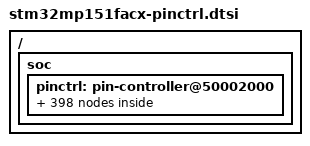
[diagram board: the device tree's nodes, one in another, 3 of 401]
/*
 * NOTE: Autogenerated file using genpinctrl.py
 *
 * SPDX-License-Identifier: Apache-2.0
 */

#include <dt-bindings/pinctrl/stm32-pinctrl.h>

/ {
	soc {
		pinctrl: pin-controller@50002000 {

			/* ADC_IN / ADC_INN / ADC_INP */

			adc1_inp16_pa0: adc1_inp16_pa0 {
				pinmux = <STM32_PINMUX('A', 0, ANALOG)>;
			};

			adc1_inn16_pa1: adc1_inn16_pa1 {
				pinmux = <STM32_PINMUX('A', 1, ANALOG)>;
			};

			adc1_inp17_pa1: adc1_inp17_pa1 {
				pinmux = <STM32_PINMUX('A', 1, ANALOG)>;
			};

			adc1_inp14_pa2: adc1_inp14_pa2 {
				pinmux = <STM32_PINMUX('A', 2, ANALOG)>;
			};

			adc1_inp15_pa3: adc1_inp15_pa3 {
				pinmux = <STM32_PINMUX('A', 3, ANALOG)>;
			};

			adc1_inp18_pa4: adc1_inp18_pa4 {
				pinmux = <STM32_PINMUX('A', 4, ANALOG)>;
			};

			adc1_inn18_pa5: adc1_inn18_pa5 {
				pinmux = <STM32_PINMUX('A', 5, ANALOG)>;
			};

			adc1_inp19_pa5: adc1_inp19_pa5 {
				pinmux = <STM32_PINMUX('A', 5, ANALOG)>;
			};

			adc1_inp3_pa6: adc1_inp3_pa6 {
				pinmux = <STM32_PINMUX('A', 6, ANALOG)>;
			};

			adc1_inn3_pa7: adc1_inn3_pa7 {
				pinmux = <STM32_PINMUX('A', 7, ANALOG)>;
			};

			adc1_inp7_pa7: adc1_inp7_pa7 {
				pinmux = <STM32_PINMUX('A', 7, ANALOG)>;
			};

			adc1_inn5_pb0: adc1_inn5_pb0 {
				pinmux = <STM32_PINMUX('B', 0, ANALOG)>;
			};

			adc1_inp9_pb0: adc1_inp9_pb0 {
				pinmux = <STM32_PINMUX('B', 0, ANALOG)>;
			};

			adc1_inp5_pb1: adc1_inp5_pb1 {
				pinmux = <STM32_PINMUX('B', 1, ANALOG)>;
			};

			adc1_inp10_pc0: adc1_inp10_pc0 {
				pinmux = <STM32_PINMUX('C', 0, ANALOG)>;
			};

			adc1_inn10_pc1: adc1_inn10_pc1 {
				pinmux = <STM32_PINMUX('C', 1, ANALOG)>;
			};

			adc1_inp11_pc1: adc1_inp11_pc1 {
				pinmux = <STM32_PINMUX('C', 1, ANALOG)>;
			};

			adc1_inn11_pc2: adc1_inn11_pc2 {
				pinmux = <STM32_PINMUX('C', 2, ANALOG)>;
			};

			adc1_inp12_pc2: adc1_inp12_pc2 {
				pinmux = <STM32_PINMUX('C', 2, ANALOG)>;
			};

			adc1_inn12_pc3: adc1_inn12_pc3 {
				pinmux = <STM32_PINMUX('C', 3, ANALOG)>;
			};

			adc1_inp13_pc3: adc1_inp13_pc3 {
				pinmux = <STM32_PINMUX('C', 3, ANALOG)>;
			};

			adc1_inp4_pc4: adc1_inp4_pc4 {
				pinmux = <STM32_PINMUX('C', 4, ANALOG)>;
			};

			adc1_inn4_pc5: adc1_inn4_pc5 {
				pinmux = <STM32_PINMUX('C', 5, ANALOG)>;
			};

			adc1_inp8_pc5: adc1_inp8_pc5 {
				pinmux = <STM32_PINMUX('C', 5, ANALOG)>;
			};

			adc1_inp2_pf11: adc1_inp2_pf11 {
				pinmux = <STM32_PINMUX('F', 11, ANALOG)>;
			};

			adc1_inn2_pf12: adc1_inn2_pf12 {
				pinmux = <STM32_PINMUX('F', 12, ANALOG)>;
			};

			adc1_inp6_pf12: adc1_inp6_pf12 {
				pinmux = <STM32_PINMUX('F', 12, ANALOG)>;
			};

			adc2_inp18_pa4: adc2_inp18_pa4 {
				pinmux = <STM32_PINMUX('A', 4, ANALOG)>;
			};

			adc2_inn18_pa5: adc2_inn18_pa5 {
				pinmux = <STM32_PINMUX('A', 5, ANALOG)>;
			};

			adc2_inp19_pa5: adc2_inp19_pa5 {
				pinmux = <STM32_PINMUX('A', 5, ANALOG)>;
			};

			adc2_inp3_pa6: adc2_inp3_pa6 {
				pinmux = <STM32_PINMUX('A', 6, ANALOG)>;
			};

			adc2_inn3_pa7: adc2_inn3_pa7 {
				pinmux = <STM32_PINMUX('A', 7, ANALOG)>;
			};

			adc2_inp7_pa7: adc2_inp7_pa7 {
				pinmux = <STM32_PINMUX('A', 7, ANALOG)>;
			};

			adc2_inn5_pb0: adc2_inn5_pb0 {
				pinmux = <STM32_PINMUX('B', 0, ANALOG)>;
			};

			adc2_inp9_pb0: adc2_inp9_pb0 {
				pinmux = <STM32_PINMUX('B', 0, ANALOG)>;
			};

			adc2_inp5_pb1: adc2_inp5_pb1 {
				pinmux = <STM32_PINMUX('B', 1, ANALOG)>;
			};

			adc2_inp10_pc0: adc2_inp10_pc0 {
				pinmux = <STM32_PINMUX('C', 0, ANALOG)>;
			};

			adc2_inn10_pc1: adc2_inn10_pc1 {
				pinmux = <STM32_PINMUX('C', 1, ANALOG)>;
			};

			adc2_inp11_pc1: adc2_inp11_pc1 {
				pinmux = <STM32_PINMUX('C', 1, ANALOG)>;
			};

			adc2_inp4_pc4: adc2_inp4_pc4 {
				pinmux = <STM32_PINMUX('C', 4, ANALOG)>;
			};

			adc2_inn4_pc5: adc2_inn4_pc5 {
				pinmux = <STM32_PINMUX('C', 5, ANALOG)>;
			};

			adc2_inp8_pc5: adc2_inp8_pc5 {
				pinmux = <STM32_PINMUX('C', 5, ANALOG)>;
			};

			adc2_inp2_pf13: adc2_inp2_pf13 {
				pinmux = <STM32_PINMUX('F', 13, ANALOG)>;
			};

			adc2_inn2_pf14: adc2_inn2_pf14 {
				pinmux = <STM32_PINMUX('F', 14, ANALOG)>;
			};

			adc2_inp6_pf14: adc2_inp6_pf14 {
				pinmux = <STM32_PINMUX('F', 14, ANALOG)>;
			};

			/* DAC_OUT */

			dac1_out1_pa4: dac1_out1_pa4 {
				pinmux = <STM32_PINMUX('A', 4, ANALOG)>;
			};

			dac1_out2_pa5: dac1_out2_pa5 {
				pinmux = <STM32_PINMUX('A', 5, ANALOG)>;
			};

			/* I2C_SCL */

			i2c1_scl_pb6: i2c1_scl_pb6 {
				pinmux = <STM32_PINMUX('B', 6, AF4)>;
				bias-pull-up;
				drive-open-drain;
			};

			i2c1_scl_pb8: i2c1_scl_pb8 {
				pinmux = <STM32_PINMUX('B', 8, AF4)>;
				bias-pull-up;
				drive-open-drain;
			};

			i2c1_scl_pd12: i2c1_scl_pd12 {
				pinmux = <STM32_PINMUX('D', 12, AF5)>;
				bias-pull-up;
				drive-open-drain;
			};

			i2c1_scl_pf14: i2c1_scl_pf14 {
				pinmux = <STM32_PINMUX('F', 14, AF5)>;
				bias-pull-up;
				drive-open-drain;
			};

			i2c1_scl_ph11: i2c1_scl_ph11 {
				pinmux = <STM32_PINMUX('H', 11, AF5)>;
				bias-pull-up;
				drive-open-drain;
			};

			i2c2_scl_pb10: i2c2_scl_pb10 {
				pinmux = <STM32_PINMUX('B', 10, AF4)>;
				bias-pull-up;
				drive-open-drain;
			};

			i2c2_scl_pd7: i2c2_scl_pd7 {
				pinmux = <STM32_PINMUX('D', 7, AF4)>;
				bias-pull-up;
				drive-open-drain;
			};

			i2c2_scl_pf1: i2c2_scl_pf1 {
				pinmux = <STM32_PINMUX('F', 1, AF4)>;
				bias-pull-up;
				drive-open-drain;
			};

			i2c2_scl_ph4: i2c2_scl_ph4 {
				pinmux = <STM32_PINMUX('H', 4, AF4)>;
				bias-pull-up;
				drive-open-drain;
			};

			i2c2_scl_pz0: i2c2_scl_pz0 {
				pinmux = <STM32_PINMUX('Z', 0, AF3)>;
				bias-pull-up;
				drive-open-drain;
			};

			i2c2_scl_pz2: i2c2_scl_pz2 {
				pinmux = <STM32_PINMUX('Z', 2, AF3)>;
				bias-pull-up;
				drive-open-drain;
			};

			i2c2_scl_pz4: i2c2_scl_pz4 {
				pinmux = <STM32_PINMUX('Z', 4, AF3)>;
				bias-pull-up;
				drive-open-drain;
			};

			i2c2_scl_pz6: i2c2_scl_pz6 {
				pinmux = <STM32_PINMUX('Z', 6, AF3)>;
				bias-pull-up;
				drive-open-drain;
			};

			i2c3_scl_pa8: i2c3_scl_pa8 {
				pinmux = <STM32_PINMUX('A', 8, AF4)>;
				bias-pull-up;
				drive-open-drain;
			};

			i2c3_scl_ph7: i2c3_scl_ph7 {
				pinmux = <STM32_PINMUX('H', 7, AF4)>;
				bias-pull-up;
				drive-open-drain;
			};

			i2c4_scl_pb6: i2c4_scl_pb6 {
				pinmux = <STM32_PINMUX('B', 6, AF6)>;
				bias-pull-up;
				drive-open-drain;
			};

			i2c4_scl_pb8: i2c4_scl_pb8 {
				pinmux = <STM32_PINMUX('B', 8, AF6)>;
				bias-pull-up;
				drive-open-drain;
			};

			i2c4_scl_pd12: i2c4_scl_pd12 {
				pinmux = <STM32_PINMUX('D', 12, AF4)>;
				bias-pull-up;
				drive-open-drain;
			};

			i2c4_scl_pe2: i2c4_scl_pe2 {
				pinmux = <STM32_PINMUX('E', 2, AF4)>;
				bias-pull-up;
				drive-open-drain;
			};

			i2c4_scl_pf14: i2c4_scl_pf14 {
				pinmux = <STM32_PINMUX('F', 14, AF4)>;
				bias-pull-up;
				drive-open-drain;
			};

			i2c4_scl_ph11: i2c4_scl_ph11 {
				pinmux = <STM32_PINMUX('H', 11, AF4)>;
				bias-pull-up;
				drive-open-drain;
			};

			i2c4_scl_pz4: i2c4_scl_pz4 {
				pinmux = <STM32_PINMUX('Z', 4, AF6)>;
				bias-pull-up;
				drive-open-drain;
			};

			i2c5_scl_pa11: i2c5_scl_pa11 {
				pinmux = <STM32_PINMUX('A', 11, AF4)>;
				bias-pull-up;
				drive-open-drain;
			};

			i2c5_scl_pd1: i2c5_scl_pd1 {
				pinmux = <STM32_PINMUX('D', 1, AF4)>;
				bias-pull-up;
				drive-open-drain;
			};

			i2c5_scl_pz4: i2c5_scl_pz4 {
				pinmux = <STM32_PINMUX('Z', 4, AF4)>;
				bias-pull-up;
				drive-open-drain;
			};

			i2c6_scl_pa11: i2c6_scl_pa11 {
				pinmux = <STM32_PINMUX('A', 11, AF2)>;
				bias-pull-up;
				drive-open-drain;
			};

			i2c6_scl_pd1: i2c6_scl_pd1 {
				pinmux = <STM32_PINMUX('D', 1, AF2)>;
				bias-pull-up;
				drive-open-drain;
			};

			i2c6_scl_pz0: i2c6_scl_pz0 {
				pinmux = <STM32_PINMUX('Z', 0, AF2)>;
				bias-pull-up;
				drive-open-drain;
			};

			i2c6_scl_pz2: i2c6_scl_pz2 {
				pinmux = <STM32_PINMUX('Z', 2, AF2)>;
				bias-pull-up;
				drive-open-drain;
			};

			i2c6_scl_pz4: i2c6_scl_pz4 {
				pinmux = <STM32_PINMUX('Z', 4, AF2)>;
				bias-pull-up;
				drive-open-drain;
			};

			i2c6_scl_pz6: i2c6_scl_pz6 {
				pinmux = <STM32_PINMUX('Z', 6, AF2)>;
				bias-pull-up;
				drive-open-drain;
			};

			/* I2C_SDA */

			i2c1_sda_pb7: i2c1_sda_pb7 {
				pinmux = <STM32_PINMUX('B', 7, AF4)>;
				bias-pull-up;
				drive-open-drain;
			};

			i2c1_sda_pb9: i2c1_sda_pb9 {
				pinmux = <STM32_PINMUX('B', 9, AF4)>;
				bias-pull-up;
				drive-open-drain;
			};

			i2c1_sda_pd13: i2c1_sda_pd13 {
				pinmux = <STM32_PINMUX('D', 13, AF5)>;
				bias-pull-up;
				drive-open-drain;
			};

			i2c1_sda_pf15: i2c1_sda_pf15 {
				pinmux = <STM32_PINMUX('F', 15, AF5)>;
				bias-pull-up;
				drive-open-drain;
			};

			i2c1_sda_ph12: i2c1_sda_ph12 {
				pinmux = <STM32_PINMUX('H', 12, AF5)>;
				bias-pull-up;
				drive-open-drain;
			};

			i2c2_sda_pb11: i2c2_sda_pb11 {
				pinmux = <STM32_PINMUX('B', 11, AF4)>;
				bias-pull-up;
				drive-open-drain;
			};

			i2c2_sda_pf0: i2c2_sda_pf0 {
				pinmux = <STM32_PINMUX('F', 0, AF4)>;
				bias-pull-up;
				drive-open-drain;
			};

			i2c2_sda_pg15: i2c2_sda_pg15 {
				pinmux = <STM32_PINMUX('G', 15, AF4)>;
				bias-pull-up;
				drive-open-drain;
			};

			i2c2_sda_ph5: i2c2_sda_ph5 {
				pinmux = <STM32_PINMUX('H', 5, AF4)>;
				bias-pull-up;
				drive-open-drain;
			};

			i2c2_sda_pz1: i2c2_sda_pz1 {
				pinmux = <STM32_PINMUX('Z', 1, AF3)>;
				bias-pull-up;
				drive-open-drain;
			};

			i2c2_sda_pz3: i2c2_sda_pz3 {
				pinmux = <STM32_PINMUX('Z', 3, AF3)>;
				bias-pull-up;
				drive-open-drain;
			};

			i2c2_sda_pz5: i2c2_sda_pz5 {
				pinmux = <STM32_PINMUX('Z', 5, AF3)>;
				bias-pull-up;
				drive-open-drain;
			};

			i2c2_sda_pz7: i2c2_sda_pz7 {
				pinmux = <STM32_PINMUX('Z', 7, AF3)>;
				bias-pull-up;
				drive-open-drain;
			};

			i2c3_sda_pc9: i2c3_sda_pc9 {
				pinmux = <STM32_PINMUX('C', 9, AF4)>;
				bias-pull-up;
				drive-open-drain;
			};

			i2c3_sda_ph8: i2c3_sda_ph8 {
				pinmux = <STM32_PINMUX('H', 8, AF4)>;
				bias-pull-up;
				drive-open-drain;
			};

			i2c4_sda_pb7: i2c4_sda_pb7 {
				pinmux = <STM32_PINMUX('B', 7, AF6)>;
				bias-pull-up;
				drive-open-drain;
			};

			i2c4_sda_pb9: i2c4_sda_pb9 {
				pinmux = <STM32_PINMUX('B', 9, AF6)>;
				bias-pull-up;
				drive-open-drain;
			};

			i2c4_sda_pd13: i2c4_sda_pd13 {
				pinmux = <STM32_PINMUX('D', 13, AF4)>;
				bias-pull-up;
				drive-open-drain;
			};

			i2c4_sda_pf15: i2c4_sda_pf15 {
				pinmux = <STM32_PINMUX('F', 15, AF4)>;
				bias-pull-up;
				drive-open-drain;
			};

			i2c4_sda_ph12: i2c4_sda_ph12 {
				pinmux = <STM32_PINMUX('H', 12, AF4)>;
				bias-pull-up;
				drive-open-drain;
			};

			i2c4_sda_pz1: i2c4_sda_pz1 {
				pinmux = <STM32_PINMUX('Z', 1, AF6)>;
				bias-pull-up;
				drive-open-drain;
			};

			i2c4_sda_pz3: i2c4_sda_pz3 {
				pinmux = <STM32_PINMUX('Z', 3, AF6)>;
				bias-pull-up;
				drive-open-drain;
			};

			i2c4_sda_pz5: i2c4_sda_pz5 {
				pinmux = <STM32_PINMUX('Z', 5, AF6)>;
				bias-pull-up;
				drive-open-drain;
			};

			i2c5_sda_pa12: i2c5_sda_pa12 {
				pinmux = <STM32_PINMUX('A', 12, AF4)>;
				bias-pull-up;
				drive-open-drain;
			};

			i2c5_sda_pd0: i2c5_sda_pd0 {
				pinmux = <STM32_PINMUX('D', 0, AF4)>;
				bias-pull-up;
				drive-open-drain;
			};

			i2c5_sda_pz1: i2c5_sda_pz1 {
				pinmux = <STM32_PINMUX('Z', 1, AF4)>;
				bias-pull-up;
				drive-open-drain;
			};

			i2c5_sda_pz3: i2c5_sda_pz3 {
				pinmux = <STM32_PINMUX('Z', 3, AF4)>;
				bias-pull-up;
				drive-open-drain;
			};

			i2c5_sda_pz5: i2c5_sda_pz5 {
				pinmux = <STM32_PINMUX('Z', 5, AF4)>;
				bias-pull-up;
				drive-open-drain;
			};

			i2c6_sda_pa12: i2c6_sda_pa12 {
				pinmux = <STM32_PINMUX('A', 12, AF2)>;
				bias-pull-up;
				drive-open-drain;
			};

			i2c6_sda_pd0: i2c6_sda_pd0 {
				pinmux = <STM32_PINMUX('D', 0, AF2)>;
				bias-pull-up;
				drive-open-drain;
			};

			i2c6_sda_pz1: i2c6_sda_pz1 {
				pinmux = <STM32_PINMUX('Z', 1, AF2)>;
				bias-pull-up;
				drive-open-drain;
			};

			i2c6_sda_pz3: i2c6_sda_pz3 {
				pinmux = <STM32_PINMUX('Z', 3, AF2)>;
				bias-pull-up;
				drive-open-drain;
			};

			i2c6_sda_pz5: i2c6_sda_pz5 {
				pinmux = <STM32_PINMUX('Z', 5, AF2)>;
				bias-pull-up;
				drive-open-drain;
			};

			i2c6_sda_pz7: i2c6_sda_pz7 {
				pinmux = <STM32_PINMUX('Z', 7, AF2)>;
				bias-pull-up;
				drive-open-drain;
			};

			/* I2S_CK */

			i2s1_ck_pa5: i2s1_ck_pa5 {
				pinmux = <STM32_PINMUX('A', 5, AF5)>;
			};

			i2s1_ck_pb3: i2s1_ck_pb3 {
				pinmux = <STM32_PINMUX('B', 3, AF5)>;
			};

			i2s1_ck_pz0: i2s1_ck_pz0 {
				pinmux = <STM32_PINMUX('Z', 0, AF5)>;
			};

			i2s2_ck_pa9: i2s2_ck_pa9 {
				pinmux = <STM32_PINMUX('A', 9, AF5)>;
			};

			i2s2_ck_pb10: i2s2_ck_pb10 {
				pinmux = <STM32_PINMUX('B', 10, AF5)>;
			};

			i2s2_ck_pb13: i2s2_ck_pb13 {
				pinmux = <STM32_PINMUX('B', 13, AF5)>;
			};

			i2s2_ck_pd3: i2s2_ck_pd3 {
				pinmux = <STM32_PINMUX('D', 3, AF5)>;
			};

			i2s2_ck_pi1: i2s2_ck_pi1 {
				pinmux = <STM32_PINMUX('I', 1, AF5)>;
			};

			i2s3_ck_pb3: i2s3_ck_pb3 {
				pinmux = <STM32_PINMUX('B', 3, AF6)>;
			};

			i2s3_ck_pc10: i2s3_ck_pc10 {
				pinmux = <STM32_PINMUX('C', 10, AF6)>;
			};

			i2s3_ck_pe0: i2s3_ck_pe0 {
				pinmux = <STM32_PINMUX('E', 0, AF5)>;
			};

			/* I2S_WS */

			i2s1_ws_pa4: i2s1_ws_pa4 {
				pinmux = <STM32_PINMUX('A', 4, AF5)>;
			};

			i2s1_ws_pa15: i2s1_ws_pa15 {
				pinmux = <STM32_PINMUX('A', 15, AF5)>;
			};

			i2s1_ws_pz3: i2s1_ws_pz3 {
				pinmux = <STM32_PINMUX('Z', 3, AF5)>;
			};

			i2s2_ws_pa11: i2s2_ws_pa11 {
				pinmux = <STM32_PINMUX('A', 11, AF5)>;
			};

			i2s2_ws_pb4: i2s2_ws_pb4 {
				pinmux = <STM32_PINMUX('B', 4, AF7)>;
			};

			i2s2_ws_pb9: i2s2_ws_pb9 {
				pinmux = <STM32_PINMUX('B', 9, AF5)>;
			};

			i2s2_ws_pb12: i2s2_ws_pb12 {
				pinmux = <STM32_PINMUX('B', 12, AF5)>;
			};

			i2s2_ws_pi0: i2s2_ws_pi0 {
				pinmux = <STM32_PINMUX('I', 0, AF5)>;
			};

			i2s3_ws_pa4: i2s3_ws_pa4 {
				pinmux = <STM32_PINMUX('A', 4, AF6)>;
			};

			i2s3_ws_pa10: i2s3_ws_pa10 {
				pinmux = <STM32_PINMUX('A', 10, AF5)>;
			};

			i2s3_ws_pa15: i2s3_ws_pa15 {
				pinmux = <STM32_PINMUX('A', 15, AF6)>;
			};

			/* SPI_MISO */

			spi1_miso_pa6: spi1_miso_pa6 {
				pinmux = <STM32_PINMUX('A', 6, AF5)>;
				bias-pull-down;
			};

			spi1_miso_pb4: spi1_miso_pb4 {
				pinmux = <STM32_PINMUX('B', 4, AF5)>;
				bias-pull-down;
			};

			spi1_miso_pz1: spi1_miso_pz1 {
				pinmux = <STM32_PINMUX('Z', 1, AF5)>;
				bias-pull-down;
			};

			spi2_miso_pb14: spi2_miso_pb14 {
				pinmux = <STM32_PINMUX('B', 14, AF5)>;
				bias-pull-down;
			};

			spi2_miso_pc2: spi2_miso_pc2 {
				pinmux = <STM32_PINMUX('C', 2, AF5)>;
				bias-pull-down;
			};

			spi2_miso_pi2: spi2_miso_pi2 {
				pinmux = <STM32_PINMUX('I', 2, AF5)>;
				bias-pull-down;
			};

			spi3_miso_pb4: spi3_miso_pb4 {
				pinmux = <STM32_PINMUX('B', 4, AF6)>;
				bias-pull-down;
			};

			spi3_miso_pc11: spi3_miso_pc11 {
				pinmux = <STM32_PINMUX('C', 11, AF6)>;
				bias-pull-down;
			};

			spi3_miso_pd10: spi3_miso_pd10 {
				pinmux = <STM32_PINMUX('D', 10, AF5)>;
				bias-pull-down;
			};

			spi4_miso_pe5: spi4_miso_pe5 {
				pinmux = <STM32_PINMUX('E', 5, AF5)>;
				bias-pull-down;
			};

			spi4_miso_pe13: spi4_miso_pe13 {
				pinmux = <STM32_PINMUX('E', 13, AF5)>;
				bias-pull-down;
			};

			spi5_miso_pf8: spi5_miso_pf8 {
				pinmux = <STM32_PINMUX('F', 8, AF5)>;
				bias-pull-down;
			};

			spi5_miso_ph7: spi5_miso_ph7 {
				pinmux = <STM32_PINMUX('H', 7, AF5)>;
				bias-pull-down;
			};

			spi6_miso_pa6: spi6_miso_pa6 {
				pinmux = <STM32_PINMUX('A', 6, AF8)>;
				bias-pull-down;
			};

			spi6_miso_pb4: spi6_miso_pb4 {
				pinmux = <STM32_PINMUX('B', 4, AF8)>;
				bias-pull-down;
			};

			spi6_miso_pg12: spi6_miso_pg12 {
				pinmux = <STM32_PINMUX('G', 12, AF5)>;
				bias-pull-down;
			};

			spi6_miso_pz1: spi6_miso_pz1 {
				pinmux = <STM32_PINMUX('Z', 1, AF8)>;
				bias-pull-down;
			};

			/* SPI_MOSI */

			spi1_mosi_pa7: spi1_mosi_pa7 {
				pinmux = <STM32_PINMUX('A', 7, AF5)>;
				bias-pull-down;
			};

			spi1_mosi_pb5: spi1_mosi_pb5 {
				pinmux = <STM32_PINMUX('B', 5, AF5)>;
				bias-pull-down;
			};

			spi1_mosi_pz2: spi1_mosi_pz2 {
				pinmux = <STM32_PINMUX('Z', 2, AF5)>;
				bias-pull-down;
			};

			spi2_mosi_pb15: spi2_mosi_pb15 {
				pinmux = <STM32_PINMUX('B', 15, AF5)>;
				bias-pull-down;
			};

			spi2_mosi_pc1: spi2_mosi_pc1 {
				pinmux = <STM32_PINMUX('C', 1, AF5)>;
				bias-pull-down;
			};

			spi2_mosi_pc3: spi2_mosi_pc3 {
				pinmux = <STM32_PINMUX('C', 3, AF5)>;
				bias-pull-down;
			};

			spi2_mosi_pi3: spi2_mosi_pi3 {
				pinmux = <STM32_PINMUX('I', 3, AF5)>;
				bias-pull-down;
			};

			spi3_mosi_pa8: spi3_mosi_pa8 {
				pinmux = <STM32_PINMUX('A', 8, AF5)>;
				bias-pull-down;
			};

			spi3_mosi_pb2: spi3_mosi_pb2 {
				pinmux = <STM32_PINMUX('B', 2, AF7)>;
				bias-pull-down;
			};

			spi3_mosi_pb5: spi3_mosi_pb5 {
				pinmux = <STM32_PINMUX('B', 5, AF7)>;
				bias-pull-down;
			};

			spi3_mosi_pc12: spi3_mosi_pc12 {
				pinmux = <STM32_PINMUX('C', 12, AF6)>;
				bias-pull-down;
			};

			spi3_mosi_pd6: spi3_mosi_pd6 {
				pinmux = <STM32_PINMUX('D', 6, AF5)>;
				bias-pull-down;
			};

			spi4_mosi_pe6: spi4_mosi_pe6 {
				pinmux = <STM32_PINMUX('E', 6, AF5)>;
				bias-pull-down;
			};

			spi4_mosi_pe14: spi4_mosi_pe14 {
				pinmux = <STM32_PINMUX('E', 14, AF5)>;
				bias-pull-down;
			};

			spi5_mosi_pf9: spi5_mosi_pf9 {
				pinmux = <STM32_PINMUX('F', 9, AF5)>;
				bias-pull-down;
			};

			spi5_mosi_pf11: spi5_mosi_pf11 {
				pinmux = <STM32_PINMUX('F', 11, AF5)>;
				bias-pull-down;
			};

			spi6_mosi_pa7: spi6_mosi_pa7 {
				pinmux = <STM32_PINMUX('A', 7, AF8)>;
				bias-pull-down;
			};

			spi6_mosi_pb5: spi6_mosi_pb5 {
				pinmux = <STM32_PINMUX('B', 5, AF8)>;
				bias-pull-down;
			};

			spi6_mosi_pg14: spi6_mosi_pg14 {
				pinmux = <STM32_PINMUX('G', 14, AF5)>;
				bias-pull-down;
			};

			spi6_mosi_pz2: spi6_mosi_pz2 {
				pinmux = <STM32_PINMUX('Z', 2, AF8)>;
				bias-pull-down;
			};

			/* SPI_NSS */

			spi1_nss_pa4: spi1_nss_pa4 {
				pinmux = <STM32_PINMUX('A', 4, AF5)>;
				bias-pull-up;
			};

			spi1_nss_pa15: spi1_nss_pa15 {
				pinmux = <STM32_PINMUX('A', 15, AF5)>;
				bias-pull-up;
			};

			spi1_nss_pz3: spi1_nss_pz3 {
				pinmux = <STM32_PINMUX('Z', 3, AF5)>;
				bias-pull-up;
			};

			spi2_nss_pa11: spi2_nss_pa11 {
				pinmux = <STM32_PINMUX('A', 11, AF5)>;
				bias-pull-up;
			};

			spi2_nss_pb4: spi2_nss_pb4 {
				pinmux = <STM32_PINMUX('B', 4, AF7)>;
				bias-pull-up;
			};

			spi2_nss_pb9: spi2_nss_pb9 {
				pinmux = <STM32_PINMUX('B', 9, AF5)>;
				bias-pull-up;
			};

			spi2_nss_pb12: spi2_nss_pb12 {
				pinmux = <STM32_PINMUX('B', 12, AF5)>;
				bias-pull-up;
			};

			spi2_nss_pi0: spi2_nss_pi0 {
				pinmux = <STM32_PINMUX('I', 0, AF5)>;
				bias-pull-up;
			};

			spi3_nss_pa4: spi3_nss_pa4 {
				pinmux = <STM32_PINMUX('A', 4, AF6)>;
				bias-pull-up;
			};

			spi3_nss_pa10: spi3_nss_pa10 {
				pinmux = <STM32_PINMUX('A', 10, AF5)>;
				bias-pull-up;
			};

			spi3_nss_pa15: spi3_nss_pa15 {
				pinmux = <STM32_PINMUX('A', 15, AF6)>;
				bias-pull-up;
			};

			spi4_nss_pe4: spi4_nss_pe4 {
				pinmux = <STM32_PINMUX('E', 4, AF5)>;
				bias-pull-up;
			};

			spi4_nss_pe11: spi4_nss_pe11 {
				pinmux = <STM32_PINMUX('E', 11, AF5)>;
				bias-pull-up;
			};

			spi5_nss_pf6: spi5_nss_pf6 {
				pinmux = <STM32_PINMUX('F', 6, AF5)>;
				bias-pull-up;
			};

			spi5_nss_ph5: spi5_nss_ph5 {
				pinmux = <STM32_PINMUX('H', 5, AF5)>;
				bias-pull-up;
			};

			spi6_nss_pa4: spi6_nss_pa4 {
				pinmux = <STM32_PINMUX('A', 4, AF8)>;
				bias-pull-up;
			};

			spi6_nss_pa15: spi6_nss_pa15 {
				pinmux = <STM32_PINMUX('A', 15, AF7)>;
				bias-pull-up;
			};

			spi6_nss_pg8: spi6_nss_pg8 {
				pinmux = <STM32_PINMUX('G', 8, AF5)>;
				bias-pull-up;
			};

			spi6_nss_pz3: spi6_nss_pz3 {
				pinmux = <STM32_PINMUX('Z', 3, AF8)>;
				bias-pull-up;
			};

			/* SPI_SCK */

			spi1_sck_pa5: spi1_sck_pa5 {
				pinmux = <STM32_PINMUX('A', 5, AF5)>;
				slew-rate = "very-high-speed";
			};

			spi1_sck_pb3: spi1_sck_pb3 {
				pinmux = <STM32_PINMUX('B', 3, AF5)>;
				slew-rate = "very-high-speed";
			};

			spi1_sck_pz0: spi1_sck_pz0 {
				pinmux = <STM32_PINMUX('Z', 0, AF5)>;
				slew-rate = "very-high-speed";
			};

			spi2_sck_pa9: spi2_sck_pa9 {
				pinmux = <STM32_PINMUX('A', 9, AF5)>;
				slew-rate = "very-high-speed";
			};

			spi2_sck_pb10: spi2_sck_pb10 {
				pinmux = <STM32_PINMUX('B', 10, AF5)>;
				slew-rate = "very-high-speed";
			};

			spi2_sck_pb13: spi2_sck_pb13 {
				pinmux = <STM32_PINMUX('B', 13, AF5)>;
				slew-rate = "very-high-speed";
			};

			spi2_sck_pd3: spi2_sck_pd3 {
				pinmux = <STM32_PINMUX('D', 3, AF5)>;
				slew-rate = "very-high-speed";
			};

			spi2_sck_pi1: spi2_sck_pi1 {
				pinmux = <STM32_PINMUX('I', 1, AF5)>;
				slew-rate = "very-high-speed";
			};

			spi3_sck_pb3: spi3_sck_pb3 {
				pinmux = <STM32_PINMUX('B', 3, AF6)>;
				slew-rate = "very-high-speed";
			};

			spi3_sck_pc10: spi3_sck_pc10 {
				pinmux = <STM32_PINMUX('C', 10, AF6)>;
				slew-rate = "very-high-speed";
			};

			spi3_sck_pe0: spi3_sck_pe0 {
				pinmux = <STM32_PINMUX('E', 0, AF5)>;
				slew-rate = "very-high-speed";
			};

			spi4_sck_pe2: spi4_sck_pe2 {
				pinmux = <STM32_PINMUX('E', 2, AF5)>;
				slew-rate = "very-high-speed";
			};

			spi4_sck_pe12: spi4_sck_pe12 {
				pinmux = <STM32_PINMUX('E', 12, AF5)>;
				slew-rate = "very-high-speed";
			};

			spi5_sck_pf7: spi5_sck_pf7 {
				pinmux = <STM32_PINMUX('F', 7, AF5)>;
				slew-rate = "very-high-speed";
			};

			spi5_sck_ph6: spi5_sck_ph6 {
				pinmux = <STM32_PINMUX('H', 6, AF5)>;
				slew-rate = "very-high-speed";
			};

			spi6_sck_pa5: spi6_sck_pa5 {
				pinmux = <STM32_PINMUX('A', 5, AF8)>;
				slew-rate = "very-high-speed";
			};

			spi6_sck_pb3: spi6_sck_pb3 {
				pinmux = <STM32_PINMUX('B', 3, AF8)>;
				slew-rate = "very-high-speed";
			};

			spi6_sck_pg13: spi6_sck_pg13 {
				pinmux = <STM32_PINMUX('G', 13, AF5)>;
				slew-rate = "very-high-speed";
			};

			spi6_sck_pz0: spi6_sck_pz0 {
				pinmux = <STM32_PINMUX('Z', 0, AF8)>;
				slew-rate = "very-high-speed";
			};

			/* TIM_CH_PWM / TIM_CHN_PWM */

			tim1_ch1n_pwm_pa7: tim1_ch1n_pwm_pa7 {
				pinmux = <STM32_PINMUX('A', 7, AF1)>;
			};

			tim1_ch1_pwm_pa8: tim1_ch1_pwm_pa8 {
				pinmux = <STM32_PINMUX('A', 8, AF1)>;
			};

			tim1_ch2_pwm_pa9: tim1_ch2_pwm_pa9 {
				pinmux = <STM32_PINMUX('A', 9, AF1)>;
			};

			tim1_ch3_pwm_pa10: tim1_ch3_pwm_pa10 {
				pinmux = <STM32_PINMUX('A', 10, AF1)>;
			};

			tim1_ch4_pwm_pa11: tim1_ch4_pwm_pa11 {
				pinmux = <STM32_PINMUX('A', 11, AF1)>;
			};

			tim1_ch2n_pwm_pb0: tim1_ch2n_pwm_pb0 {
				pinmux = <STM32_PINMUX('B', 0, AF1)>;
			};

			tim1_ch3n_pwm_pb1: tim1_ch3n_pwm_pb1 {
				pinmux = <STM32_PINMUX('B', 1, AF1)>;
			};

			tim1_ch1n_pwm_pb13: tim1_ch1n_pwm_pb13 {
				pinmux = <STM32_PINMUX('B', 13, AF1)>;
			};

			tim1_ch2n_pwm_pb14: tim1_ch2n_pwm_pb14 {
				pinmux = <STM32_PINMUX('B', 14, AF1)>;
			};

			tim1_ch3n_pwm_pb15: tim1_ch3n_pwm_pb15 {
				pinmux = <STM32_PINMUX('B', 15, AF1)>;
			};

			tim1_ch1n_pwm_pe8: tim1_ch1n_pwm_pe8 {
				pinmux = <STM32_PINMUX('E', 8, AF1)>;
			};

			tim1_ch1_pwm_pe9: tim1_ch1_pwm_pe9 {
				pinmux = <STM32_PINMUX('E', 9, AF1)>;
			};

			tim1_ch2n_pwm_pe10: tim1_ch2n_pwm_pe10 {
				pinmux = <STM32_PINMUX('E', 10, AF1)>;
			};

			tim1_ch2_pwm_pe11: tim1_ch2_pwm_pe11 {
				pinmux = <STM32_PINMUX('E', 11, AF1)>;
			};

			tim1_ch3n_pwm_pe12: tim1_ch3n_pwm_pe12 {
				pinmux = <STM32_PINMUX('E', 12, AF1)>;
			};

			tim1_ch3_pwm_pe13: tim1_ch3_pwm_pe13 {
				pinmux = <STM32_PINMUX('E', 13, AF1)>;
			};

			tim1_ch4_pwm_pe14: tim1_ch4_pwm_pe14 {
				pinmux = <STM32_PINMUX('E', 14, AF1)>;
			};

			tim2_ch1_pwm_pa0: tim2_ch1_pwm_pa0 {
				pinmux = <STM32_PINMUX('A', 0, AF1)>;
			};

			tim2_ch2_pwm_pa1: tim2_ch2_pwm_pa1 {
				pinmux = <STM32_PINMUX('A', 1, AF1)>;
			};

			tim2_ch3_pwm_pa2: tim2_ch3_pwm_pa2 {
				pinmux = <STM32_PINMUX('A', 2, AF1)>;
			};

			tim2_ch4_pwm_pa3: tim2_ch4_pwm_pa3 {
				pinmux = <STM32_PINMUX('A', 3, AF1)>;
			};

			tim2_ch1_pwm_pa5: tim2_ch1_pwm_pa5 {
				pinmux = <STM32_PINMUX('A', 5, AF1)>;
			};

			tim2_ch1_pwm_pa15: tim2_ch1_pwm_pa15 {
				pinmux = <STM32_PINMUX('A', 15, AF1)>;
			};

			tim2_ch2_pwm_pb3: tim2_ch2_pwm_pb3 {
				pinmux = <STM32_PINMUX('B', 3, AF1)>;
			};

			tim2_ch3_pwm_pb10: tim2_ch3_pwm_pb10 {
				pinmux = <STM32_PINMUX('B', 10, AF1)>;
			};

			tim2_ch4_pwm_pb11: tim2_ch4_pwm_pb11 {
				pinmux = <STM32_PINMUX('B', 11, AF1)>;
			};

			tim12_ch1_pwm_pb14: tim12_ch1_pwm_pb14 {
				pinmux = <STM32_PINMUX('B', 14, AF2)>;
			};

			tim12_ch2_pwm_pb15: tim12_ch2_pwm_pb15 {
				pinmux = <STM32_PINMUX('B', 15, AF2)>;
			};

			tim2_ch1_pwm_pg8: tim2_ch1_pwm_pg8 {
				pinmux = <STM32_PINMUX('G', 8, AF1)>;
			};

			tim12_ch1_pwm_ph6: tim12_ch1_pwm_ph6 {
				pinmux = <STM32_PINMUX('H', 6, AF2)>;
			};

			tim12_ch2_pwm_ph9: tim12_ch2_pwm_ph9 {
				pinmux = <STM32_PINMUX('H', 9, AF2)>;
			};

			tim13_ch1_pwm_pa6: tim13_ch1_pwm_pa6 {
				pinmux = <STM32_PINMUX('A', 6, AF9)>;
			};

			tim3_ch1_pwm_pa6: tim3_ch1_pwm_pa6 {
				pinmux = <STM32_PINMUX('A', 6, AF2)>;
			};

			tim3_ch2_pwm_pa7: tim3_ch2_pwm_pa7 {
				pinmux = <STM32_PINMUX('A', 7, AF2)>;
			};

			tim3_ch3_pwm_pb0: tim3_ch3_pwm_pb0 {
				pinmux = <STM32_PINMUX('B', 0, AF2)>;
			};

			tim3_ch4_pwm_pb1: tim3_ch4_pwm_pb1 {
				pinmux = <STM32_PINMUX('B', 1, AF2)>;
			};

			tim3_ch1_pwm_pb4: tim3_ch1_pwm_pb4 {
				pinmux = <STM32_PINMUX('B', 4, AF2)>;
			};

			tim3_ch2_pwm_pb5: tim3_ch2_pwm_pb5 {
				pinmux = <STM32_PINMUX('B', 5, AF2)>;
			};

			tim3_ch1_pwm_pc6: tim3_ch1_pwm_pc6 {
				pinmux = <STM32_PINMUX('C', 6, AF2)>;
			};

			tim3_ch2_pwm_pc7: tim3_ch2_pwm_pc7 {
				pinmux = <STM32_PINMUX('C', 7, AF2)>;
			};

			tim3_ch3_pwm_pc8: tim3_ch3_pwm_pc8 {
				pinmux = <STM32_PINMUX('C', 8, AF2)>;
			};

			tim3_ch4_pwm_pc9: tim3_ch4_pwm_pc9 {
				pinmux = <STM32_PINMUX('C', 9, AF2)>;
			};

			tim13_ch1_pwm_pf8: tim13_ch1_pwm_pf8 {
				pinmux = <STM32_PINMUX('F', 8, AF9)>;
			};

			tim14_ch1_pwm_pa7: tim14_ch1_pwm_pa7 {
				pinmux = <STM32_PINMUX('A', 7, AF9)>;
			};

			tim4_ch1_pwm_pb6: tim4_ch1_pwm_pb6 {
				pinmux = <STM32_PINMUX('B', 6, AF2)>;
			};

			tim4_ch2_pwm_pb7: tim4_ch2_pwm_pb7 {
				pinmux = <STM32_PINMUX('B', 7, AF2)>;
			};

			tim4_ch3_pwm_pb8: tim4_ch3_pwm_pb8 {
				pinmux = <STM32_PINMUX('B', 8, AF2)>;
			};

			tim4_ch4_pwm_pb9: tim4_ch4_pwm_pb9 {
				pinmux = <STM32_PINMUX('B', 9, AF2)>;
			};

			tim4_ch1_pwm_pd12: tim4_ch1_pwm_pd12 {
				pinmux = <STM32_PINMUX('D', 12, AF2)>;
			};

			tim4_ch2_pwm_pd13: tim4_ch2_pwm_pd13 {
				pinmux = <STM32_PINMUX('D', 13, AF2)>;
			};

			tim4_ch3_pwm_pd14: tim4_ch3_pwm_pd14 {
				pinmux = <STM32_PINMUX('D', 14, AF2)>;
			};

			tim4_ch4_pwm_pd15: tim4_ch4_pwm_pd15 {
				pinmux = <STM32_PINMUX('D', 15, AF2)>;
			};

			tim14_ch1_pwm_pf9: tim14_ch1_pwm_pf9 {
				pinmux = <STM32_PINMUX('F', 9, AF9)>;
			};

			tim5_ch1_pwm_pa0: tim5_ch1_pwm_pa0 {
				pinmux = <STM32_PINMUX('A', 0, AF2)>;
			};

			tim15_ch1n_pwm_pa1: tim15_ch1n_pwm_pa1 {
				pinmux = <STM32_PINMUX('A', 1, AF4)>;
			};

			tim5_ch2_pwm_pa1: tim5_ch2_pwm_pa1 {
				pinmux = <STM32_PINMUX('A', 1, AF2)>;
			};

			tim15_ch1_pwm_pa2: tim15_ch1_pwm_pa2 {
				pinmux = <STM32_PINMUX('A', 2, AF4)>;
			};

			tim5_ch3_pwm_pa2: tim5_ch3_pwm_pa2 {
				pinmux = <STM32_PINMUX('A', 2, AF2)>;
			};

			tim15_ch2_pwm_pa3: tim15_ch2_pwm_pa3 {
				pinmux = <STM32_PINMUX('A', 3, AF4)>;
			};

			tim5_ch4_pwm_pa3: tim5_ch4_pwm_pa3 {
				pinmux = <STM32_PINMUX('A', 3, AF2)>;
			};

			tim15_ch1n_pwm_pe4: tim15_ch1n_pwm_pe4 {
				pinmux = <STM32_PINMUX('E', 4, AF4)>;
			};

			tim15_ch1_pwm_pe5: tim15_ch1_pwm_pe5 {
				pinmux = <STM32_PINMUX('E', 5, AF4)>;
			};

			tim15_ch2_pwm_pe6: tim15_ch2_pwm_pe6 {
				pinmux = <STM32_PINMUX('E', 6, AF4)>;
			};

			tim5_ch1_pwm_ph10: tim5_ch1_pwm_ph10 {
				pinmux = <STM32_PINMUX('H', 10, AF2)>;
			};

			tim5_ch2_pwm_ph11: tim5_ch2_pwm_ph11 {
				pinmux = <STM32_PINMUX('H', 11, AF2)>;
			};

			tim5_ch3_pwm_ph12: tim5_ch3_pwm_ph12 {
				pinmux = <STM32_PINMUX('H', 12, AF2)>;
			};

			tim5_ch4_pwm_pi0: tim5_ch4_pwm_pi0 {
				pinmux = <STM32_PINMUX('I', 0, AF2)>;
			};

			tim16_ch1n_pwm_pb6: tim16_ch1n_pwm_pb6 {
				pinmux = <STM32_PINMUX('B', 6, AF1)>;
			};

			tim16_ch1_pwm_pb8: tim16_ch1_pwm_pb8 {
				pinmux = <STM32_PINMUX('B', 8, AF1)>;
			};

			tim16_ch1n_pwm_pd6: tim16_ch1n_pwm_pd6 {
				pinmux = <STM32_PINMUX('D', 6, AF1)>;
			};

			tim16_ch1_pwm_pf6: tim16_ch1_pwm_pf6 {
				pinmux = <STM32_PINMUX('F', 6, AF1)>;
			};

			tim16_ch1n_pwm_pf8: tim16_ch1n_pwm_pf8 {
				pinmux = <STM32_PINMUX('F', 8, AF1)>;
			};

			tim17_ch1n_pwm_pb7: tim17_ch1n_pwm_pb7 {
				pinmux = <STM32_PINMUX('B', 7, AF1)>;
			};

			tim17_ch1_pwm_pb9: tim17_ch1_pwm_pb9 {
				pinmux = <STM32_PINMUX('B', 9, AF1)>;
			};

			tim17_ch1_pwm_pf7: tim17_ch1_pwm_pf7 {
				pinmux = <STM32_PINMUX('F', 7, AF1)>;
			};

			tim17_ch1n_pwm_pf9: tim17_ch1n_pwm_pf9 {
				pinmux = <STM32_PINMUX('F', 9, AF1)>;
			};

			tim8_ch1n_pwm_pa5: tim8_ch1n_pwm_pa5 {
				pinmux = <STM32_PINMUX('A', 5, AF3)>;
			};

			tim8_ch1n_pwm_pa7: tim8_ch1n_pwm_pa7 {
				pinmux = <STM32_PINMUX('A', 7, AF3)>;
			};

			tim8_ch2n_pwm_pb0: tim8_ch2n_pwm_pb0 {
				pinmux = <STM32_PINMUX('B', 0, AF3)>;
			};

			tim8_ch3n_pwm_pb1: tim8_ch3n_pwm_pb1 {
				pinmux = <STM32_PINMUX('B', 1, AF3)>;
			};

			tim8_ch2n_pwm_pb14: tim8_ch2n_pwm_pb14 {
				pinmux = <STM32_PINMUX('B', 14, AF3)>;
			};

			tim8_ch3n_pwm_pb15: tim8_ch3n_pwm_pb15 {
				pinmux = <STM32_PINMUX('B', 15, AF3)>;
			};

			tim8_ch1_pwm_pc6: tim8_ch1_pwm_pc6 {
				pinmux = <STM32_PINMUX('C', 6, AF3)>;
			};

			tim8_ch2_pwm_pc7: tim8_ch2_pwm_pc7 {
				pinmux = <STM32_PINMUX('C', 7, AF3)>;
			};

			tim8_ch3_pwm_pc8: tim8_ch3_pwm_pc8 {
				pinmux = <STM32_PINMUX('C', 8, AF3)>;
			};

			tim8_ch4_pwm_pc9: tim8_ch4_pwm_pc9 {
				pinmux = <STM32_PINMUX('C', 9, AF3)>;
			};

			tim8_ch1n_pwm_ph13: tim8_ch1n_pwm_ph13 {
				pinmux = <STM32_PINMUX('H', 13, AF3)>;
			};

			tim8_ch2n_pwm_ph14: tim8_ch2n_pwm_ph14 {
				pinmux = <STM32_PINMUX('H', 14, AF3)>;
			};

			tim8_ch3n_pwm_ph15: tim8_ch3n_pwm_ph15 {
				pinmux = <STM32_PINMUX('H', 15, AF3)>;
			};

			tim8_ch4_pwm_pi2: tim8_ch4_pwm_pi2 {
				pinmux = <STM32_PINMUX('I', 2, AF3)>;
			};

			tim8_ch1_pwm_pi5: tim8_ch1_pwm_pi5 {
				pinmux = <STM32_PINMUX('I', 5, AF3)>;
			};

			tim8_ch2_pwm_pi6: tim8_ch2_pwm_pi6 {
				pinmux = <STM32_PINMUX('I', 6, AF3)>;
			};

			tim8_ch3_pwm_pi7: tim8_ch3_pwm_pi7 {
				pinmux = <STM32_PINMUX('I', 7, AF3)>;
			};

			/* UART_CTS / USART_CTS / LPUART_CTS */

			usart1_cts_pa11: usart1_cts_pa11 {
				pinmux = <STM32_PINMUX('A', 11, AF7)>;
				bias-pull-up;
				drive-open-drain;
			};

			usart1_cts_pz3: usart1_cts_pz3 {
				pinmux = <STM32_PINMUX('Z', 3, AF7)>;
				bias-pull-up;
				drive-open-drain;
			};

			usart2_cts_pa0: usart2_cts_pa0 {
				pinmux = <STM32_PINMUX('A', 0, AF7)>;
				bias-pull-up;
				drive-open-drain;
			};

			usart2_cts_pd3: usart2_cts_pd3 {
				pinmux = <STM32_PINMUX('D', 3, AF7)>;
				bias-pull-up;
				drive-open-drain;
			};

			usart2_cts_pe15: usart2_cts_pe15 {
				pinmux = <STM32_PINMUX('E', 15, AF7)>;
				bias-pull-up;
				drive-open-drain;
			};

			usart3_cts_pb13: usart3_cts_pb13 {
				pinmux = <STM32_PINMUX('B', 13, AF7)>;
				bias-pull-up;
				drive-open-drain;
			};

			usart3_cts_pd11: usart3_cts_pd11 {
				pinmux = <STM32_PINMUX('D', 11, AF7)>;
				bias-pull-up;
				drive-open-drain;
			};

			usart3_cts_pi10: usart3_cts_pi10 {
				pinmux = <STM32_PINMUX('I', 10, AF8)>;
				bias-pull-up;
				drive-open-drain;
			};

			uart4_cts_pb0: uart4_cts_pb0 {
				pinmux = <STM32_PINMUX('B', 0, AF8)>;
				bias-pull-up;
				drive-open-drain;
			};

			uart5_cts_pc9: uart5_cts_pc9 {
				pinmux = <STM32_PINMUX('C', 9, AF8)>;
				bias-pull-up;
				drive-open-drain;
			};

			usart6_cts_pg13: usart6_cts_pg13 {
				pinmux = <STM32_PINMUX('G', 13, AF7)>;
				bias-pull-up;
				drive-open-drain;
			};

			usart6_cts_pg15: usart6_cts_pg15 {
				pinmux = <STM32_PINMUX('G', 15, AF7)>;
				bias-pull-up;
				drive-open-drain;
			};

			uart7_cts_pe10: uart7_cts_pe10 {
				pinmux = <STM32_PINMUX('E', 10, AF7)>;
				bias-pull-up;
				drive-open-drain;
			};

			uart7_cts_pf9: uart7_cts_pf9 {
				pinmux = <STM32_PINMUX('F', 9, AF7)>;
				bias-pull-up;
				drive-open-drain;
			};

			uart8_cts_pd14: uart8_cts_pd14 {
				pinmux = <STM32_PINMUX('D', 14, AF8)>;
				bias-pull-up;
				drive-open-drain;
			};

			uart8_cts_pd15: uart8_cts_pd15 {
				pinmux = <STM32_PINMUX('D', 15, AF8)>;
				bias-pull-up;
				drive-open-drain;
			};

			uart8_cts_pe15: uart8_cts_pe15 {
				pinmux = <STM32_PINMUX('E', 15, AF8)>;
				bias-pull-up;
				drive-open-drain;
			};

			uart8_cts_pg10: uart8_cts_pg10 {
				pinmux = <STM32_PINMUX('G', 10, AF8)>;
				bias-pull-up;
				drive-open-drain;
			};

			/* UART_RTS / USART_RTS / LPUART_RTS */

			usart1_rts_pa12: usart1_rts_pa12 {
				pinmux = <STM32_PINMUX('A', 12, AF7)>;
				bias-pull-up;
				drive-open-drain;
			};

			usart1_rts_pz5: usart1_rts_pz5 {
				pinmux = <STM32_PINMUX('Z', 5, AF7)>;
				bias-pull-up;
				drive-open-drain;
			};

			usart2_rts_pa1: usart2_rts_pa1 {
				pinmux = <STM32_PINMUX('A', 1, AF7)>;
				bias-pull-up;
				drive-open-drain;
			};

			usart2_rts_pd4: usart2_rts_pd4 {
				pinmux = <STM32_PINMUX('D', 4, AF7)>;
				bias-pull-up;
				drive-open-drain;
			};

			usart3_rts_pb14: usart3_rts_pb14 {
				pinmux = <STM32_PINMUX('B', 14, AF7)>;
				bias-pull-up;
				drive-open-drain;
			};

			usart3_rts_pd12: usart3_rts_pd12 {
				pinmux = <STM32_PINMUX('D', 12, AF7)>;
				bias-pull-up;
				drive-open-drain;
			};

			usart3_rts_pg8: usart3_rts_pg8 {
				pinmux = <STM32_PINMUX('G', 8, AF8)>;
				bias-pull-up;
				drive-open-drain;
			};

			uart4_rts_pa15: uart4_rts_pa15 {
				pinmux = <STM32_PINMUX('A', 15, AF8)>;
				bias-pull-up;
				drive-open-drain;
			};

			uart5_rts_pc8: uart5_rts_pc8 {
				pinmux = <STM32_PINMUX('C', 8, AF8)>;
				bias-pull-up;
				drive-open-drain;
			};

			usart6_rts_pg8: usart6_rts_pg8 {
				pinmux = <STM32_PINMUX('G', 8, AF7)>;
				bias-pull-up;
				drive-open-drain;
			};

			usart6_rts_pg12: usart6_rts_pg12 {
				pinmux = <STM32_PINMUX('G', 12, AF7)>;
				bias-pull-up;
				drive-open-drain;
			};

			uart7_rts_pe9: uart7_rts_pe9 {
				pinmux = <STM32_PINMUX('E', 9, AF7)>;
				bias-pull-up;
				drive-open-drain;
			};

			uart7_rts_pf8: uart7_rts_pf8 {
				pinmux = <STM32_PINMUX('F', 8, AF7)>;
				bias-pull-up;
				drive-open-drain;
			};

			uart8_rts_pe14: uart8_rts_pe14 {
				pinmux = <STM32_PINMUX('E', 14, AF8)>;
				bias-pull-up;
				drive-open-drain;
			};

			uart8_rts_pg7: uart8_rts_pg7 {
				pinmux = <STM32_PINMUX('G', 7, AF8)>;
				bias-pull-up;
				drive-open-drain;
			};

			/* UART_RX / USART_RX / LPUART_RX */

			usart1_rx_pa10: usart1_rx_pa10 {
				pinmux = <STM32_PINMUX('A', 10, AF7)>;
			};

			usart1_rx_pb2: usart1_rx_pb2 {
				pinmux = <STM32_PINMUX('B', 2, AF4)>;
			};

			usart1_rx_pb7: usart1_rx_pb7 {
				pinmux = <STM32_PINMUX('B', 7, AF7)>;
			};

			usart1_rx_pb15: usart1_rx_pb15 {
				pinmux = <STM32_PINMUX('B', 15, AF4)>;
			};

			usart1_rx_pz1: usart1_rx_pz1 {
				pinmux = <STM32_PINMUX('Z', 1, AF7)>;
			};

			usart1_rx_pz6: usart1_rx_pz6 {
				pinmux = <STM32_PINMUX('Z', 6, AF7)>;
			};

			usart2_rx_pa3: usart2_rx_pa3 {
				pinmux = <STM32_PINMUX('A', 3, AF7)>;
			};

			usart2_rx_pd6: usart2_rx_pd6 {
				pinmux = <STM32_PINMUX('D', 6, AF7)>;
			};

			usart2_rx_pf4: usart2_rx_pf4 {
				pinmux = <STM32_PINMUX('F', 4, AF7)>;
			};

			usart3_rx_pb11: usart3_rx_pb11 {
				pinmux = <STM32_PINMUX('B', 11, AF7)>;
			};

			usart3_rx_pb12: usart3_rx_pb12 {
				pinmux = <STM32_PINMUX('B', 12, AF8)>;
			};

			usart3_rx_pc11: usart3_rx_pc11 {
				pinmux = <STM32_PINMUX('C', 11, AF7)>;
			};

			usart3_rx_pd9: usart3_rx_pd9 {
				pinmux = <STM32_PINMUX('D', 9, AF7)>;
			};

			uart4_rx_pa1: uart4_rx_pa1 {
				pinmux = <STM32_PINMUX('A', 1, AF8)>;
			};

			uart4_rx_pa11: uart4_rx_pa11 {
				pinmux = <STM32_PINMUX('A', 11, AF6)>;
			};

			uart4_rx_pb2: uart4_rx_pb2 {
				pinmux = <STM32_PINMUX('B', 2, AF8)>;
			};

			uart4_rx_pb8: uart4_rx_pb8 {
				pinmux = <STM32_PINMUX('B', 8, AF8)>;
			};

			uart4_rx_pc11: uart4_rx_pc11 {
				pinmux = <STM32_PINMUX('C', 11, AF8)>;
			};

			uart4_rx_pd0: uart4_rx_pd0 {
				pinmux = <STM32_PINMUX('D', 0, AF8)>;
			};

			uart4_rx_pd2: uart4_rx_pd2 {
				pinmux = <STM32_PINMUX('D', 2, AF6)>;
			};

			uart4_rx_ph14: uart4_rx_ph14 {
				pinmux = <STM32_PINMUX('H', 14, AF8)>;
			};

			uart4_rx_pi9: uart4_rx_pi9 {
				pinmux = <STM32_PINMUX('I', 9, AF8)>;
			};

			uart5_rx_pb5: uart5_rx_pb5 {
				pinmux = <STM32_PINMUX('B', 5, AF12)>;
			};

			uart5_rx_pb12: uart5_rx_pb12 {
				pinmux = <STM32_PINMUX('B', 12, AF14)>;
			};

			uart5_rx_pd2: uart5_rx_pd2 {
				pinmux = <STM32_PINMUX('D', 2, AF8)>;
			};

			usart6_rx_pc7: usart6_rx_pc7 {
				pinmux = <STM32_PINMUX('C', 7, AF7)>;
			};

			usart6_rx_pg9: usart6_rx_pg9 {
				pinmux = <STM32_PINMUX('G', 9, AF7)>;
			};

			uart7_rx_pa8: uart7_rx_pa8 {
				pinmux = <STM32_PINMUX('A', 8, AF13)>;
			};

			uart7_rx_pb3: uart7_rx_pb3 {
				pinmux = <STM32_PINMUX('B', 3, AF13)>;
			};

			uart7_rx_pe7: uart7_rx_pe7 {
				pinmux = <STM32_PINMUX('E', 7, AF7)>;
			};

			uart7_rx_pf6: uart7_rx_pf6 {
				pinmux = <STM32_PINMUX('F', 6, AF7)>;
			};

			uart8_rx_pe0: uart8_rx_pe0 {
				pinmux = <STM32_PINMUX('E', 0, AF8)>;
			};

			/* UART_TX / USART_TX / LPUART_TX */

			usart1_tx_pa9: usart1_tx_pa9 {
				pinmux = <STM32_PINMUX('A', 9, AF7)>;
				bias-pull-up;
			};

			usart1_tx_pb6: usart1_tx_pb6 {
				pinmux = <STM32_PINMUX('B', 6, AF7)>;
				bias-pull-up;
			};

			usart1_tx_pb14: usart1_tx_pb14 {
				pinmux = <STM32_PINMUX('B', 14, AF4)>;
				bias-pull-up;
			};

			usart1_tx_pg11: usart1_tx_pg11 {
				pinmux = <STM32_PINMUX('G', 11, AF4)>;
				bias-pull-up;
			};

			usart1_tx_pz2: usart1_tx_pz2 {
				pinmux = <STM32_PINMUX('Z', 2, AF7)>;
				bias-pull-up;
			};

			usart1_tx_pz7: usart1_tx_pz7 {
				pinmux = <STM32_PINMUX('Z', 7, AF7)>;
				bias-pull-up;
			};

			usart2_tx_pa2: usart2_tx_pa2 {
				pinmux = <STM32_PINMUX('A', 2, AF7)>;
				bias-pull-up;
			};

			usart2_tx_pd5: usart2_tx_pd5 {
				pinmux = <STM32_PINMUX('D', 5, AF7)>;
				bias-pull-up;
			};

			usart2_tx_pf5: usart2_tx_pf5 {
				pinmux = <STM32_PINMUX('F', 5, AF7)>;
				bias-pull-up;
			};

			usart3_tx_pb10: usart3_tx_pb10 {
				pinmux = <STM32_PINMUX('B', 10, AF7)>;
				bias-pull-up;
			};

			usart3_tx_pc10: usart3_tx_pc10 {
				pinmux = <STM32_PINMUX('C', 10, AF7)>;
				bias-pull-up;
			};

			usart3_tx_pd8: usart3_tx_pd8 {
				pinmux = <STM32_PINMUX('D', 8, AF7)>;
				bias-pull-up;
			};

			uart4_tx_pa0: uart4_tx_pa0 {
				pinmux = <STM32_PINMUX('A', 0, AF8)>;
				bias-pull-up;
			};

			uart4_tx_pa12: uart4_tx_pa12 {
				pinmux = <STM32_PINMUX('A', 12, AF6)>;
				bias-pull-up;
			};

			uart4_tx_pa13: uart4_tx_pa13 {
				pinmux = <STM32_PINMUX('A', 13, AF8)>;
				bias-pull-up;
			};

			uart4_tx_pb9: uart4_tx_pb9 {
				pinmux = <STM32_PINMUX('B', 9, AF8)>;
				bias-pull-up;
			};

			uart4_tx_pc8: uart4_tx_pc8 {
				pinmux = <STM32_PINMUX('C', 8, AF6)>;
				bias-pull-up;
			};

			uart4_tx_pc10: uart4_tx_pc10 {
				pinmux = <STM32_PINMUX('C', 10, AF8)>;
				bias-pull-up;
			};

			uart4_tx_pd1: uart4_tx_pd1 {
				pinmux = <STM32_PINMUX('D', 1, AF8)>;
				bias-pull-up;
			};

			uart4_tx_pg11: uart4_tx_pg11 {
				pinmux = <STM32_PINMUX('G', 11, AF6)>;
				bias-pull-up;
			};

			uart4_tx_ph13: uart4_tx_ph13 {
				pinmux = <STM32_PINMUX('H', 13, AF8)>;
				bias-pull-up;
			};

			uart5_tx_pb6: uart5_tx_pb6 {
				pinmux = <STM32_PINMUX('B', 6, AF12)>;
				bias-pull-up;
			};

			uart5_tx_pb13: uart5_tx_pb13 {
				pinmux = <STM32_PINMUX('B', 13, AF14)>;
				bias-pull-up;
			};

			uart5_tx_pc12: uart5_tx_pc12 {
				pinmux = <STM32_PINMUX('C', 12, AF8)>;
				bias-pull-up;
			};

			usart6_tx_pc6: usart6_tx_pc6 {
				pinmux = <STM32_PINMUX('C', 6, AF7)>;
				bias-pull-up;
			};

			usart6_tx_pg14: usart6_tx_pg14 {
				pinmux = <STM32_PINMUX('G', 14, AF7)>;
				bias-pull-up;
			};

			uart7_tx_pa15: uart7_tx_pa15 {
				pinmux = <STM32_PINMUX('A', 15, AF13)>;
				bias-pull-up;
			};

			uart7_tx_pb4: uart7_tx_pb4 {
				pinmux = <STM32_PINMUX('B', 4, AF13)>;
				bias-pull-up;
			};

			uart7_tx_pe8: uart7_tx_pe8 {
				pinmux = <STM32_PINMUX('E', 8, AF7)>;
				bias-pull-up;
			};

			uart7_tx_pf7: uart7_tx_pf7 {
				pinmux = <STM32_PINMUX('F', 7, AF7)>;
				bias-pull-up;
			};

			uart8_tx_pe1: uart8_tx_pe1 {
				pinmux = <STM32_PINMUX('E', 1, AF8)>;
				bias-pull-up;
			};

		};
	};
};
